# STM32U599 register map
File version: 0.2
CPU: CM33 r0p1, little endian, MPU, FPU, 4 interrupt priority bits
Registers are 32-bit, read-write, reset 0x0 unless marked. A register's access mark holds for its fields unless they carry their own. Offsets are from the block's base; [hi:lo] are bit positions; 'fields as' and 'values as' point back to an identical list.

## DMA2D — DMA2D controller
Base 0x4002B000
Same registers: SEC_DMA2D 0x5002B000
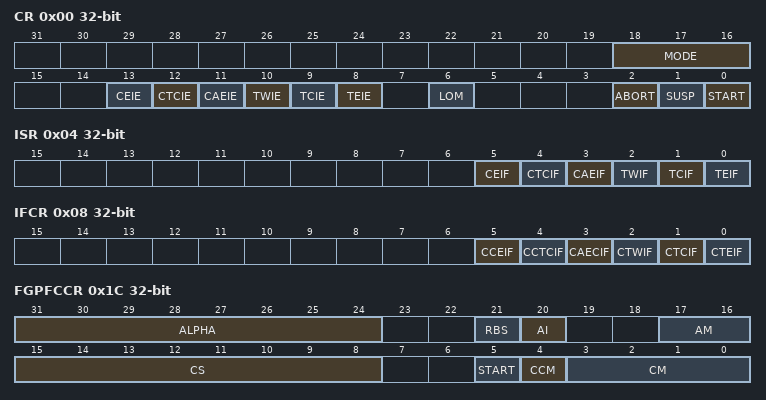
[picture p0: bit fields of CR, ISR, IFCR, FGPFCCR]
0x00 CR — control register
  [18:16] MODE — DMA2D mode
  [13] CEIE — Configuration Error Interrupt Enable
  [12] CTCIE — CLUT transfer complete interrupt enable
  [11] CAEIE — CLUT access error interrupt enable
  [10] TWIE — Transfer watermark interrupt enable
  [9] TCIE — Transfer complete interrupt enable
  [8] TEIE — Transfer error interrupt enable
  [6] LOM — Line Offset Mode
  [2] ABORT
  [1] SUSP — Suspend
  [0] START
0x04 ISR ro — Interrupt Status Register
  [5] CEIF — Configuration error interrupt flag
  [4] CTCIF — CLUT transfer complete interrupt flag
  [3] CAEIF — CLUT access error interrupt flag
  [2] TWIF — Transfer watermark interrupt flag
  [1] TCIF — Transfer complete interrupt flag
  [0] TEIF — Transfer error interrupt flag
0x08 IFCR — interrupt flag clear register
  [5] CCEIF — Clear configuration error interrupt flag
  [4] CCTCIF — Clear CLUT transfer complete interrupt flag
  [3] CAECIF — Clear CLUT access error interrupt flag
  [2] CTWIF — Clear transfer watermark interrupt flag
  [1] CTCIF — Clear transfer complete interrupt flag
  [0] CTEIF — Clear Transfer error interrupt flag
0x0C FGMAR — foreground memory address register
  [31:0] MA — Memory address
0x10 FGOR — foreground offset register
  [15:0] LO — Line offset
0x14 BGMAR — background memory address register
  [31:0] MA — Memory address
0x18 BGOR — background offset register
  [15:0] LO — Line offset
0x1C FGPFCCR — foreground PFC control register
  [31:24] ALPHA — Alpha value
  [21] RBS — Red Blue Swap
  [20] AI — Alpha Inverted
  [17:16] AM — Alpha mode
  [15:8] CS — CLUT size
  [5] START
  [4] CCM — CLUT color mode
  [3:0] CM — Color mode
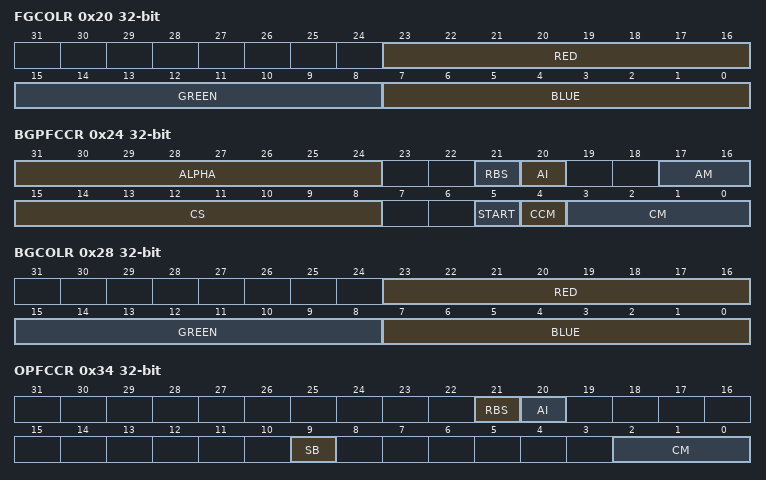
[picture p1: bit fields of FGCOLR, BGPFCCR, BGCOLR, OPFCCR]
0x20 FGCOLR — foreground color register
  [23:16] RED — Red Value
  [15:8] GREEN — Green Value
  [7:0] BLUE — Blue Value
0x24 BGPFCCR — background PFC control register
  [31:24] ALPHA — Alpha value
  [21] RBS — Red Blue Swap
  [20] AI — Alpha Inverted
  [17:16] AM — Alpha mode
  [15:8] CS — CLUT size
  [5] START
  [4] CCM — CLUT Color mode
  [3:0] CM — Color mode
0x28 BGCOLR — background color register
  fields as FGCOLR
0x2C FGCMAR — foreground CLUT memory address register
  [31:0] MA — Memory Address
0x30 BGCMAR — background CLUT memory address register
  [31:0] MA — Memory address
0x34 OPFCCR — output PFC control register
  [21] RBS — Red Blue Swap
  [20] AI — Alpha Inverted
  [9] SB — Swap Bytes
  [2:0] CM — Color mode
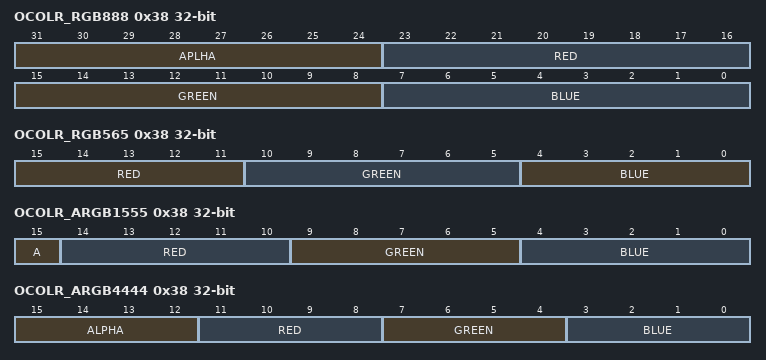
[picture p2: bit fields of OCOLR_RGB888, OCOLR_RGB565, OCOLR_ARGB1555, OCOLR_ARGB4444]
0x38 OCOLR_RGB888 — output color register
  [31:24] APLHA — Alpha Channel Value
  [23:16] RED — Red Value
  [15:8] GREEN — Green Value
  [7:0] BLUE — Blue Value
0x38 OCOLR_RGB565 (alternate view of OCOLR_RGB888) — output color register
  [15:11] RED — Red value in RGB565 mode
  [10:5] GREEN — Green value in RGB565 mode
  [4:0] BLUE — Blue value in RGB565 mode
0x38 OCOLR_ARGB1555 (alternate view of OCOLR_RGB888) — output color register
  [15] A — Alpha channel value in ARGB1555 mode
  [14:10] RED — Red value in ARGB1555 mode
  [9:5] GREEN — Green value in ARGB1555 mode
  [4:0] BLUE — Blue value in ARGB1555 mode
0x38 OCOLR_ARGB4444 (alternate view of OCOLR_RGB888) — output color register
  [15:12] ALPHA — Alpha channel value in ARGB4444
  [11:8] RED — Red value in ARGB4444 mode
  [7:4] GREEN — Green value in ARGB4444 mode
  [3:0] BLUE — Blue value in ARGB4444 mode
0x3C OMAR — output memory address register
  [31:0] MA — Memory Address
0x40 OOR — output offset register
  [15:0] LO — Line Offset
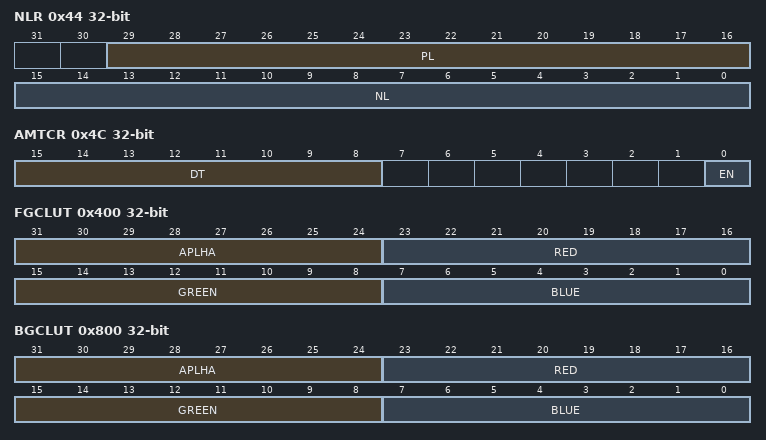
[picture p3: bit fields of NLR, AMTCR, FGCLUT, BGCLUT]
0x44 NLR — number of line register
  [29:16] PL — Pixel per lines
  [15:0] NL — Number of lines
0x48 LWR — line watermark register
  [15:0] LW — Line watermark
0x4C AMTCR — AHB master timer configuration register
  [15:8] DT — Dead Time
  [0] EN — Enable
0x400 FGCLUT
  [31:24] APLHA, [23:16] RED, [15:8] GREEN, [7:0] BLUE
0x800 BGCLUT
  [31:24] APLHA, [23:16] RED, [15:8] GREEN, [7:0] BLUE
